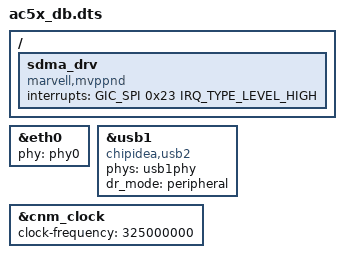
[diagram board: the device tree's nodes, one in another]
// SPDX-License-Identifier: (GPL-2.0+ OR MIT)
/*
 * Device Tree For AC5X.
 *
 * Copyright (C) 2021 Marvell
 *
 */
// SPDX-License-Identifier: (GPL-2.0+ OR MIT)
/*
 * Device Tree file for Marvell Alleycat 5X development board
 * This board file supports the B configuration of the board
 */

#include "ac5.dtsi"


&eth0 {
	status = "okay";
	phy = <&phy0>;
};

&usb1 {
	compatible = "chipidea,usb2";
	phys = <&usb1phy>;
	phy-names = "usb-phy";
	dr_mode = "peripheral";
};

&cnm_clock {
    clock-frequency = <325000000>;
};

/{
	sdma_drv {
		compatible = "marvell,mvppnd";
		interrupts = <GIC_SPI 0x23 IRQ_TYPE_LEVEL_HIGH>;
		status = "okay";
	};

};
